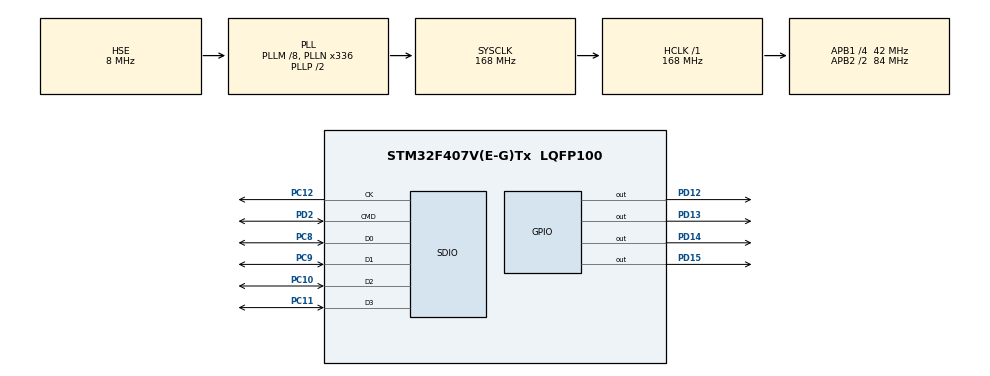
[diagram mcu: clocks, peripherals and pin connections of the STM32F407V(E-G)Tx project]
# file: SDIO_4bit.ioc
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Dma.Request0=SDIO_RX
Dma.Request1=SDIO_TX
Dma.SDIO_RX.0.Direction=DMA_PERIPH_TO_MEMORY
Dma.SDIO_RX.0.FIFOMode=DMA_FIFOMODE_ENABLE
Dma.SDIO_RX.0.FIFOThreshold=DMA_FIFO_THRESHOLD_FULL
Dma.SDIO_RX.0.Instance=DMA2_Stream3
Dma.SDIO_RX.0.MemBurst=DMA_MBURST_INC4
Dma.SDIO_RX.0.MemDataAlignment=DMA_MDATAALIGN_WORD
Dma.SDIO_RX.0.MemInc=DMA_MINC_ENABLE
Dma.SDIO_RX.0.Mode=DMA_PFCTRL
Dma.SDIO_RX.0.PeriphBurst=DMA_PBURST_INC4
Dma.SDIO_RX.0.PeriphDataAlignment=DMA_PDATAALIGN_WORD
Dma.SDIO_RX.0.PeriphInc=DMA_PINC_DISABLE
Dma.SDIO_RX.0.Priority=DMA_PRIORITY_LOW
Dma.SDIO_TX.1.Direction=DMA_MEMORY_TO_PERIPH
Dma.SDIO_TX.1.FIFOMode=DMA_FIFOMODE_ENABLE
Dma.SDIO_TX.1.FIFOThreshold=DMA_FIFO_THRESHOLD_FULL
Dma.SDIO_TX.1.Instance=DMA2_Stream6
Dma.SDIO_TX.1.MemBurst=DMA_MBURST_INC4
Dma.SDIO_TX.1.MemDataAlignment=DMA_MDATAALIGN_WORD
Dma.SDIO_TX.1.MemInc=DMA_MINC_ENABLE
Dma.SDIO_TX.1.Mode=DMA_PFCTRL
Dma.SDIO_TX.1.PeriphBurst=DMA_PBURST_INC4
Dma.SDIO_TX.1.PeriphDataAlignment=DMA_PDATAALIGN_WORD
Dma.SDIO_TX.1.PeriphInc=DMA_PINC_DISABLE
Dma.SDIO_TX.1.Priority=DMA_PRIORITY_LOW
FATFS._MAX_SS=4096
Mcu.Family=STM32F4
Mcu.Name=STM32F407V(E-G)Tx
Mcu.Package=LQFP100
NVIC.DMA2_Stream3_IRQn=true\:0\:0\:false\:false\:true\:false
NVIC.DMA2_Stream6_IRQn=true\:0\:0\:false\:false\:true\:false
NVIC.PriorityGroup=NVIC_PRIORITYGROUP_0
NVIC.SDIO_IRQn=true\:0\:0\:false\:false\:true\:true
PA13.Mode=Serial_Wire
PA13.Signal=SYS_JTMS-SWDIO
PA14.Mode=Serial_Wire
PA14.Signal=SYS_JTCK-SWCLK
PC10.Mode=SD_4_bits_Wide_bus
PC10.Signal=SDIO_D2
PC11.Mode=SD_4_bits_Wide_bus
PC11.Signal=SDIO_D3
PC12.Mode=SD_4_bits_Wide_bus
PC12.Signal=SDIO_CK
PC8.Mode=SD_4_bits_Wide_bus
PC8.Signal=SDIO_D0
PC9.Mode=SD_4_bits_Wide_bus
PC9.Signal=SDIO_D1
PD12.Signal=GPIO_Output
PD13.Signal=GPIO_Output
PD14.Signal=GPIO_Output
PD15.Signal=GPIO_Output
PD2.Mode=SD_4_bits_Wide_bus
PD2.Signal=SDIO_CMD
PH0-OSC_IN.Mode=HSE-External-Oscillator
PH0-OSC_IN.Signal=RCC_OSC_IN
PH1-OSC_OUT.Mode=HSE-External-Oscillator
PH1-OSC_OUT.Signal=RCC_OSC_OUT
ProjectManager.HeapSize=0x2000
ProjectManager.StackSize=0x4000
ProjectManager.TargetToolchain=TrueSTUDIO
RCC.48MHZClocksFreq_Value=48000000
RCC.AHBFreq_Value=168000000
RCC.APB1CLKDivider=RCC_HCLK_DIV4
RCC.APB1Freq_Value=42000000
RCC.APB1TimFreq_Value=84000000
RCC.APB2CLKDivider=RCC_HCLK_DIV2
RCC.APB2Freq_Value=84000000
RCC.APB2TimFreq_Value=168000000
RCC.CortexFreq_Value=168000000
RCC.HCLKFreq_Value=168000000
RCC.HSE_VALUE=8000000
RCC.HSI_VALUE=16000000
RCC.LSE_VALUE=32768
RCC.PLLM=8
RCC.PLLN=336
RCC.PLLQ=7
RCC.PLLSourceVirtual=RCC_PLLSOURCE_HSE
RCC.SYSCLKFreq_VALUE=168000000
RCC.SYSCLKSource=RCC_SYSCLKSOURCE_PLLCLK
RCC.VCOOutputFreq_Value=336000000
SDIO.ClockDiv=6
VP_FATFS_VS_SDIO.Mode=SDIO
board=STM32F4DISCOVERY

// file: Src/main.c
/**
  ******************************************************************************
  * @file           : main.c
  * @brief          : Main program body
  ******************************************************************************
  * This notice applies to any and all portions of this file
  * that are not between comment pairs USER CODE BEGIN and
  * USER CODE END. Other portions of this file, whether
  * inserted by the user or by software development tools
  * are owned by their respective copyright owners.
  *
  * Copyright (c) 2018 STMicroelectronics International N.V.
  * All rights reserved.
  *
  * Redistribution and use in source and binary forms, with or without
  * modification, are permitted, provided that the following conditions are met:
  *
  * 1. Redistribution of source code must retain the above copyright notice,
  *    this list of conditions and the following disclaimer.
  * 2. Redistributions in binary form must reproduce the above copyright notice,
  *    this list of conditions and the following disclaimer in the documentation
  *    and/or other materials provided with the distribution.
  * 3. Neither the name of STMicroelectronics nor the names of other
  *    contributors to this software may be used to endorse or promote products
  *    derived from this software without specific written permission.
  * 4. This software, including modifications and/or derivative works of this
  *    software, must execute solely and exclusively on microcontroller or
  *    microprocessor devices manufactured by or for STMicroelectronics.
  * 5. Redistribution and use of this software other than as permitted under
  *    this license is void and will automatically terminate your rights under
  *    this license.
  *
  * THIS SOFTWARE IS PROVIDED BY STMICROELECTRONICS AND CONTRIBUTORS "AS IS"
  * AND ANY EXPRESS, IMPLIED OR STATUTORY WARRANTIES, INCLUDING, BUT NOT
  * LIMITED TO, THE IMPLIED WARRANTIES OF MERCHANTABILITY, FITNESS FOR A
  * PARTICULAR PURPOSE AND NON-INFRINGEMENT OF THIRD PARTY INTELLECTUAL PROPERTY
  * RIGHTS ARE DISCLAIMED TO THE FULLEST EXTENT PERMITTED BY LAW. IN NO EVENT
  * SHALL STMICROELECTRONICS OR CONTRIBUTORS BE LIABLE FOR ANY DIRECT, INDIRECT,
  * INCIDENTAL, SPECIAL, EXEMPLARY, OR CONSEQUENTIAL DAMAGES (INCLUDING, BUT NOT
  * LIMITED TO, PROCUREMENT OF SUBSTITUTE GOODS OR SERVICES; LOSS OF USE, DATA,
  * OR PROFITS; OR BUSINESS INTERRUPTION) HOWEVER CAUSED AND ON ANY THEORY OF
  * LIABILITY, WHETHER IN CONTRACT, STRICT LIABILITY, OR TORT (INCLUDING
  * NEGLIGENCE OR OTHERWISE) ARISING IN ANY WAY OUT OF THE USE OF THIS SOFTWARE,
  * EVEN IF ADVISED OF THE POSSIBILITY OF SUCH DAMAGE.
  *
  ******************************************************************************
  */
#include "main.h"
#include "stm32f4xx_hal.h"
#include "dma.h"
#include "fatfs.h"
#include "sdio.h"
#include "gpio.h"

/* USER CODE BEGIN PV */
/* Private variables ---------------------------------------------------------*/

/* USER CODE END PV */

void SystemClock_Config(void);

/* USER CODE BEGIN PFP */
/* Private function prototypes -----------------------------------------------*/

/* USER CODE END PFP */

/* USER CODE BEGIN 0 */
FATFS myFatFS;
FIL myFile;
UINT myBytes;
/* USER CODE END 0 */

int main(void)
{

  /* MCU Configuration----------------------------------------------------------*/

  /* Reset of all peripherals, Initializes the Flash interface and the Systick. */
  HAL_Init();

  /* Configure the system clock */
  SystemClock_Config();

  /* Initialize all configured peripherals */
  MX_GPIO_Init();
  MX_DMA_Init();
  MX_SDIO_SD_Init();
  MX_FATFS_Init();
  /* USER CODE BEGIN 2 */

  HAL_Delay(10);

  if(f_mount(&myFatFS, SDPath, 1) == FR_OK)
  {
  	HAL_GPIO_WritePin(GPIOD, GPIO_PIN_12, GPIO_PIN_SET);

  	char myFileName[] = "0627001.txt";

  	if (f_open(&myFile, myFileName, FA_WRITE | FA_CREATE_ALWAYS) == FR_OK)
  	{
  		HAL_GPIO_WritePin(GPIOD, GPIO_PIN_13, GPIO_PIN_SET);

  		char myData[] = "STM32F4-Discovery. This is SDIO 4-bit mode!!!";

  		if(f_write(&myFile, myData, sizeof(myData), &myBytes) == FR_OK)
  		{
  			HAL_GPIO_WritePin(GPIOD, GPIO_PIN_15, GPIO_PIN_SET);
  		}

  		f_close(&myFile);
  	}
  }
  else 	HAL_GPIO_WritePin(GPIOD, GPIO_PIN_14, GPIO_PIN_SET);
  /* USER CODE END 2 */

  /* Infinite loop */
  while (1)
  {

  }

}

void SystemClock_Config(void)
{

  RCC_OscInitTypeDef RCC_OscInitStruct;
  RCC_ClkInitTypeDef RCC_ClkInitStruct;

    /**Configure the main internal regulator output voltage
    */
  __HAL_RCC_PWR_CLK_ENABLE();

  __HAL_PWR_VOLTAGESCALING_CONFIG(PWR_REGULATOR_VOLTAGE_SCALE1);

    /**Initializes the CPU, AHB and APB busses clocks
    */
  RCC_OscInitStruct.OscillatorType = RCC_OSCILLATORTYPE_HSE;
  RCC_OscInitStruct.HSEState = RCC_HSE_ON;
  RCC_OscInitStruct.PLL.PLLState = RCC_PLL_ON;
  RCC_OscInitStruct.PLL.PLLSource = RCC_PLLSOURCE_HSE;
  RCC_OscInitStruct.PLL.PLLM = 8;
  RCC_OscInitStruct.PLL.PLLN = 336;
  RCC_OscInitStruct.PLL.PLLP = RCC_PLLP_DIV2;
  RCC_OscInitStruct.PLL.PLLQ = 7;
  if (HAL_RCC_OscConfig(&RCC_OscInitStruct) != HAL_OK)
  {
    _Error_Handler(__FILE__, __LINE__);
  }

    /**Initializes the CPU, AHB and APB busses clocks
    */
  RCC_ClkInitStruct.ClockType = RCC_CLOCKTYPE_HCLK|RCC_CLOCKTYPE_SYSCLK
                              |RCC_CLOCKTYPE_PCLK1|RCC_CLOCKTYPE_PCLK2;
  RCC_ClkInitStruct.SYSCLKSource = RCC_SYSCLKSOURCE_PLLCLK;
  RCC_ClkInitStruct.AHBCLKDivider = RCC_SYSCLK_DIV1;
  RCC_ClkInitStruct.APB1CLKDivider = RCC_HCLK_DIV4;
  RCC_ClkInitStruct.APB2CLKDivider = RCC_HCLK_DIV2;

  if (HAL_RCC_ClockConfig(&RCC_ClkInitStruct, FLASH_LATENCY_5) != HAL_OK)
  {
    _Error_Handler(__FILE__, __LINE__);
  }

    /**Configure the Systick interrupt time
    */
  HAL_SYSTICK_Config(HAL_RCC_GetHCLKFreq()/1000);

    /**Configure the Systick
    */
  HAL_SYSTICK_CLKSourceConfig(SYSTICK_CLKSOURCE_HCLK);

  /* SysTick_IRQn interrupt configuration */
  HAL_NVIC_SetPriority(SysTick_IRQn, 0, 0);
}

void _Error_Handler(char *file, int line)
{
  while(1)
  {
  }
}

/************************ (C) COPYRIGHT STMicroelectronics *****END OF FILE****/
